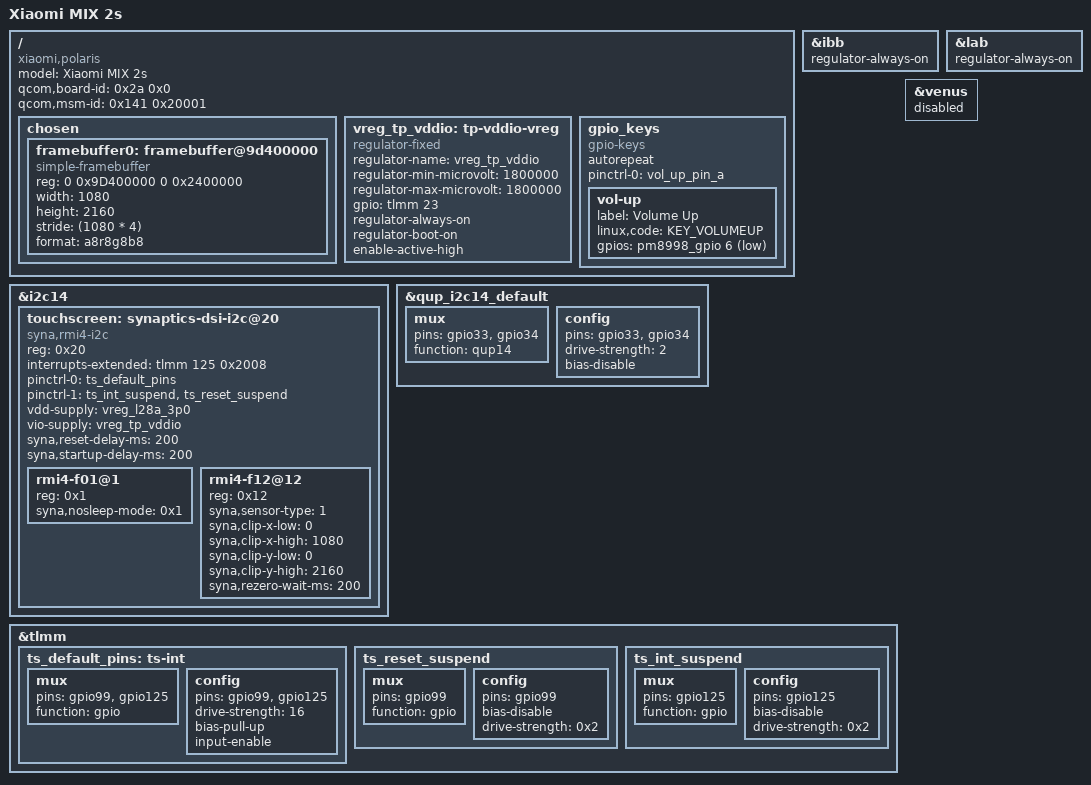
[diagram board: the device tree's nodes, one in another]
// SPDX-License-Identifier: GPL-2.0
/*
 * Copyright (c) 2021, Xilin Wu <strongtz@yeah.net>
 */

#include "sdm845-xiaomi-common.dtsi"

/ {
	model = "Xiaomi MIX 2s";
	compatible = "xiaomi,polaris", "qcom,sdm845";
	/* required for bootloader to select correct board */
	qcom,board-id = <0x2a 0x0>;
	qcom,msm-id = <0x141 0x20001>;

	chosen {
		framebuffer0: framebuffer@9d400000 {
			compatible = "simple-framebuffer";
			reg = <0 0x9D400000 0 0x2400000>;
			width = <1080>;
			height = <2160>;
			stride = <(1080 * 4)>;
			format = "a8r8g8b8";
			status = "okay";
		};
	};

	vreg_tp_vddio: tp-vddio-vreg {
		compatible = "regulator-fixed";
		regulator-name = "vreg_tp_vddio";
		
		regulator-min-microvolt = <1800000>;
		regulator-max-microvolt = <1800000>;
		
		gpio = <&tlmm 23 0>;
		regulator-always-on;
		regulator-boot-on;
		enable-active-high;
	};

	gpio_keys {
		compatible = "gpio-keys";
		autorepeat;

		pinctrl-names = "default";
		pinctrl-0 = <&vol_up_pin_a>;

		vol-up {
			label = "Volume Up";
			linux,code = <KEY_VOLUMEUP>;
			gpios = <&pm8998_gpio 6 GPIO_ACTIVE_LOW>;
		};
	};

};

// Keep these always on until we get panel driver working 
&ibb {
	regulator-always-on;
};

&lab {
	regulator-always-on;
};

/* touchscreen */
&i2c14 {
	touchscreen: synaptics-dsi-i2c@20 {
		compatible = "syna,rmi4-i2c";
		reg = <0x20>;
		#address-cells = <1>;
		#size-cells = <0>;
		interrupts-extended = <&tlmm 125 0x2008>;
		
		pinctrl-names = "default", "sleep";
		pinctrl-0 = <&ts_default_pins>;
		pinctrl-1 = <&ts_int_suspend &ts_reset_suspend>;
		
		vdd-supply = <&vreg_l28a_3p0>;
		vio-supply = <&vreg_tp_vddio>;
		
		syna,reset-delay-ms = <200>;
		syna,startup-delay-ms = <200>;

		rmi4-f01@1 {
			reg = <0x1>;
			syna,nosleep-mode = <0x1>;
		};

		rmi4-f12@12 {
			reg = <0x12>;
			syna,sensor-type = <1>;
			syna,clip-x-low = <0>;
			syna,clip-x-high = <1080>;
			syna,clip-y-low = <0>;
			syna,clip-y-high = <2160>;
			syna,rezero-wait-ms = <200>;
		};
	};
};

&qup_i2c14_default {
	mux {
		pins = "gpio33", "gpio34";
		function = "qup14";
	};
	config {
		pins = "gpio33", "gpio34";
		drive-strength = <2>;
		bias-disable;
	};
};

&tlmm {
	ts_default_pins: ts-int {
		mux {
			pins = "gpio99", "gpio125";
			function = "gpio";
		};

		config {
			pins = "gpio99", "gpio125";
			drive-strength = <16>;
			bias-pull-up;
			input-enable;
		};
	};

	ts_reset_suspend: ts_reset_suspend {
		mux {
			pins = "gpio99";
			function = "gpio";
		};

		config {
			pins = "gpio99";
			bias-disable;
			drive-strength = <0x2>;
		};
	};

	ts_int_suspend: ts_int_suspend {
		mux {
			pins = "gpio125";
			function = "gpio";
		};

		config {
			pins = "gpio125";
			bias-disable;
			drive-strength = <0x2>;
		};
	};
};

&venus {
	status = "disabled";
};

